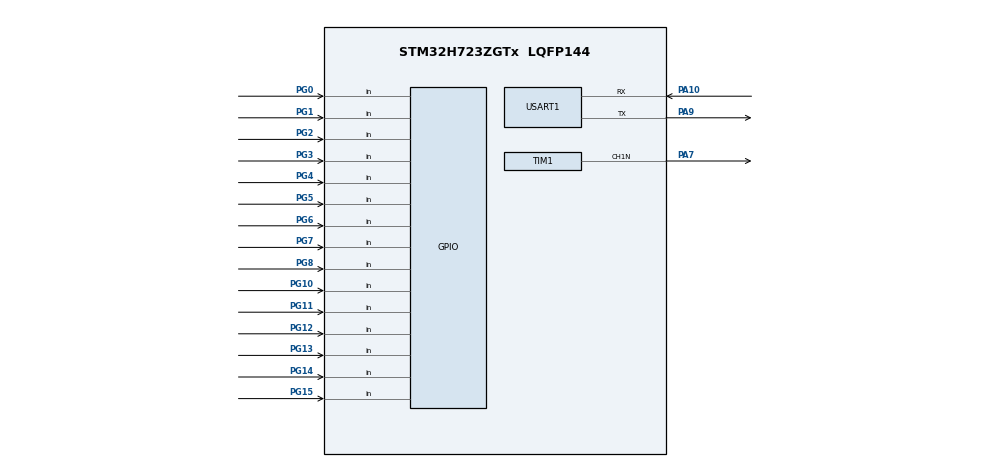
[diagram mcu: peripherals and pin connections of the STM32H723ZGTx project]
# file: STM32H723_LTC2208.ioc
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CORTEX_M7.AccessPermission_Spec=MPU_REGION_FULL_ACCESS
CORTEX_M7.BaseAddress_Spec=0x24000000
CORTEX_M7.CPU_DCache=Enabled
CORTEX_M7.CPU_ICache=Enabled
CORTEX_M7.DisableExec_Spec=MPU_INSTRUCTION_ACCESS_ENABLE
CORTEX_M7.IsBufferable_Spec=MPU_ACCESS_BUFFERABLE
CORTEX_M7.IsCacheable_Spec=MPU_ACCESS_CACHEABLE
CORTEX_M7.IsShareable_Spec=MPU_ACCESS_NOT_SHAREABLE
CORTEX_M7.Size_Spec=MPU_REGION_SIZE_512KB
CORTEX_M7.SubRegionDisable_Spec=0x00
CORTEX_M7.TypeExtField_Spec=MPU_TEX_LEVEL1
CORTEX_M7.default_mode_Activation=1
Dma.Request0=TIM1_UP
Dma.TIM1_UP.0.Direction=DMA_PERIPH_TO_MEMORY
Dma.TIM1_UP.0.EventEnable=DISABLE
Dma.TIM1_UP.0.FIFOMode=DMA_FIFOMODE_DISABLE
Dma.TIM1_UP.0.Instance=DMA1_Stream0
Dma.TIM1_UP.0.MemDataAlignment=DMA_MDATAALIGN_HALFWORD
Dma.TIM1_UP.0.MemInc=DMA_MINC_ENABLE
Dma.TIM1_UP.0.Mode=DMA_CIRCULAR
Dma.TIM1_UP.0.PeriphDataAlignment=DMA_PDATAALIGN_HALFWORD
Dma.TIM1_UP.0.PeriphInc=DMA_PINC_DISABLE
Dma.TIM1_UP.0.Polarity=HAL_DMAMUX_REQ_GEN_RISING
Dma.TIM1_UP.0.Priority=DMA_PRIORITY_VERY_HIGH
Dma.TIM1_UP.0.RequestNumber=1
Dma.TIM1_UP.0.SignalID=NONE
Dma.TIM1_UP.0.SyncEnable=DISABLE
Dma.TIM1_UP.0.SyncPolarity=HAL_DMAMUX_SYNC_NO_EVENT
Dma.TIM1_UP.0.SyncRequestNumber=1
Dma.TIM1_UP.0.SyncSignalID=NONE
Mcu.Family=STM32H7
Mcu.Name=STM32H723ZGTx
Mcu.Package=LQFP144
NVIC.DMA1_Stream0_IRQn=true\:0\:0\:false\:false\:true\:false\:true\:true
NVIC.PriorityGroup=NVIC_PRIORITYGROUP_4
PA10.Mode=Asynchronous
PA10.Signal=USART1_RX
PA13(JTMS/SWDIO).Mode=Serial_Wire
PA13(JTMS/SWDIO).Signal=DEBUG_JTMS-SWDIO
PA14(JTCK/SWCLK).Mode=Serial_Wire
PA14(JTCK/SWCLK).Signal=DEBUG_JTCK-SWCLK
PA7.GPIO_Speed=GPIO_SPEED_FREQ_VERY_HIGH
PA7.Mode=PWM Generation1 CH1N
PA7.Signal=TIM1_CH1N
PA9.Mode=Asynchronous
PA9.Signal=USART1_TX
PG0.Signal=GPIO_Input
PG1.Signal=GPIO_Input
PG10.Signal=GPIO_Input
PG11.Signal=GPIO_Input
PG12.Signal=GPIO_Input
PG13.Signal=GPIO_Input
PG14.Signal=GPIO_Input
PG15.Signal=GPIO_Input
PG2.Signal=GPIO_Input
PG3.Signal=GPIO_Input
PG4.Signal=GPIO_Input
PG5.Signal=GPIO_Input
PG6.Signal=GPIO_Input
PG7.Signal=GPIO_Input
PG8.Signal=GPIO_Input
PH0-OSC_IN.Mode=HSE-External-Oscillator
PH0-OSC_IN.Signal=RCC_OSC_IN
PH1-OSC_OUT.Mode=HSE-External-Oscillator
PH1-OSC_OUT.Signal=RCC_OSC_OUT
ProjectManager.HeapSize=0x200
ProjectManager.StackSize=0x400
ProjectManager.TargetToolchain=MDK-ARM V5.32
RCC.ADCFreq_Value=50390625
RCC.APB1Freq_Value=130000000
RCC.APB2Freq_Value=130000000
RCC.APB3Freq_Value=130000000
RCC.APB4Freq_Value=130000000
RCC.CortexFreq_Value=520000000
RCC.D1PPRE=RCC_APB3_DIV2
RCC.D2PPRE1=RCC_APB1_DIV2
RCC.D2PPRE2=RCC_APB2_DIV2
RCC.D3PPRE=RCC_APB4_DIV2
RCC.DIVM1=5
RCC.DIVN1=104
RCC.DIVP1=1
RCC.HCLKFreq_Value=260000000
RCC.HPRE=RCC_HCLK_DIV2
RCC.PLLFRACN=0
RCC.PLLSourceVirtual=RCC_PLLSOURCE_HSE
RCC.SYSCLKFreq_VALUE=520000000
RCC.SYSCLKSource=RCC_SYSCLKSOURCE_PLLCLK
RCC.USBFreq_Value=260000000
TIM1.AutoReloadPreload=TIM_AUTORELOAD_PRELOAD_ENABLE
TIM1.Channel-PWM\ Generation1\ CH1N=TIM_CHANNEL_1
TIM1.OCFastMode_PWM-PWM\ Generation1\ CH1N=TIM_OCFAST_ENABLE
TIM1.Period=0
TIM1.TIM_MasterOutputTrigger=TIM_TRGO_UPDATE
USART1.VirtualMode-Asynchronous=VM_ASYNC
VP_TIM1_VS_ClockSourceINT.Mode=Internal
board=custom

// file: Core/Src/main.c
/* USER CODE BEGIN Header */
/**
  ******************************************************************************
  * @file           : main.c
  * @brief          : Main program body
  ******************************************************************************
  * @attention
  *
  * Copyright (c) 2025 STMicroelectronics.
  * All rights reserved.
  *
  * This software is licensed under terms that can be found in the LICENSE file
  * in the root directory of this software component.
  * If no LICENSE file comes with this software, it is provided AS-IS.
  *
  ******************************************************************************
  */
/* USER CODE END Header */
#include "main.h"
#include "dma.h"
#include "tim.h"
#include "usart.h"
#include "gpio.h"

void SystemClock_Config(void);
static void MPU_Config(void);

int main(void)
{

  /* MPU Configuration--------------------------------------------------------*/
  MPU_Config();

  /* Enable I-Cache---------------------------------------------------------*/
  SCB_EnableICache();

  /* Enable D-Cache---------------------------------------------------------*/
  SCB_EnableDCache();

  /* MCU Configuration--------------------------------------------------------*/

  /* Reset of all peripherals, Initializes the Flash interface and the Systick. */
  HAL_Init();

  /* Configure the system clock */
  SystemClock_Config();

  /* Initialize all configured peripherals */
  MX_GPIO_Init();
  MX_DMA_Init();
  MX_TIM1_Init();
  MX_USART1_UART_Init();
  /* USER CODE BEGIN 2 */

	TIM1->ARR = 2500-1;
	TIM1->CCR1 = 1250;
	HAL_TIM_PWM_Start(&htim1, TIM_CHANNEL_1);
	HAL_TIMEx_PWMN_Start(&htim1, TIM_CHANNEL_1);

  /* USER CODE END 2 */

  /* Infinite loop */
  while (1)
  {

  }
}

void SystemClock_Config(void)
{
  RCC_OscInitTypeDef RCC_OscInitStruct = {0};
  RCC_ClkInitTypeDef RCC_ClkInitStruct = {0};

  /** Supply configuration update enable
  */
  HAL_PWREx_ConfigSupply(PWR_LDO_SUPPLY);

  /** Configure the main internal regulator output voltage
  */
  __HAL_PWR_VOLTAGESCALING_CONFIG(PWR_REGULATOR_VOLTAGE_SCALE0);

  while(!__HAL_PWR_GET_FLAG(PWR_FLAG_VOSRDY)) {}

  /** Initializes the RCC Oscillators according to the specified parameters
  * in the RCC_OscInitTypeDef structure.
  */
  RCC_OscInitStruct.OscillatorType = RCC_OSCILLATORTYPE_HSE;
  RCC_OscInitStruct.HSEState = RCC_HSE_ON;
  RCC_OscInitStruct.PLL.PLLState = RCC_PLL_ON;
  RCC_OscInitStruct.PLL.PLLSource = RCC_PLLSOURCE_HSE;
  RCC_OscInitStruct.PLL.PLLM = 5;
  RCC_OscInitStruct.PLL.PLLN = 104;
  RCC_OscInitStruct.PLL.PLLP = 1;
  RCC_OscInitStruct.PLL.PLLQ = 2;
  RCC_OscInitStruct.PLL.PLLR = 2;
  RCC_OscInitStruct.PLL.PLLRGE = RCC_PLL1VCIRANGE_2;
  RCC_OscInitStruct.PLL.PLLVCOSEL = RCC_PLL1VCOWIDE;
  RCC_OscInitStruct.PLL.PLLFRACN = 0;
  if (HAL_RCC_OscConfig(&RCC_OscInitStruct) != HAL_OK)
  {
    Error_Handler();
  }

  /** Initializes the CPU, AHB and APB buses clocks
  */
  RCC_ClkInitStruct.ClockType = RCC_CLOCKTYPE_HCLK|RCC_CLOCKTYPE_SYSCLK
                              |RCC_CLOCKTYPE_PCLK1|RCC_CLOCKTYPE_PCLK2
                              |RCC_CLOCKTYPE_D3PCLK1|RCC_CLOCKTYPE_D1PCLK1;
  RCC_ClkInitStruct.SYSCLKSource = RCC_SYSCLKSOURCE_PLLCLK;
  RCC_ClkInitStruct.SYSCLKDivider = RCC_SYSCLK_DIV1;
  RCC_ClkInitStruct.AHBCLKDivider = RCC_HCLK_DIV2;
  RCC_ClkInitStruct.APB3CLKDivider = RCC_APB3_DIV2;
  RCC_ClkInitStruct.APB1CLKDivider = RCC_APB1_DIV2;
  RCC_ClkInitStruct.APB2CLKDivider = RCC_APB2_DIV2;
  RCC_ClkInitStruct.APB4CLKDivider = RCC_APB4_DIV2;

  if (HAL_RCC_ClockConfig(&RCC_ClkInitStruct, FLASH_LATENCY_3) != HAL_OK)
  {
    Error_Handler();
  }
}

/* MPU Configuration */

void MPU_Config(void)
{
  MPU_Region_InitTypeDef MPU_InitStruct = {0};

  /* Disables the MPU */
  HAL_MPU_Disable();

  /** Initializes and configures the Region and the memory to be protected
  */
  MPU_InitStruct.Enable = MPU_REGION_ENABLE;
  MPU_InitStruct.Number = MPU_REGION_NUMBER0;
  MPU_InitStruct.BaseAddress = 0x24000000;
  MPU_InitStruct.Size = MPU_REGION_SIZE_512KB;
  MPU_InitStruct.SubRegionDisable = 0x00;
  MPU_InitStruct.TypeExtField = MPU_TEX_LEVEL1;
  MPU_InitStruct.AccessPermission = MPU_REGION_FULL_ACCESS;
  MPU_InitStruct.DisableExec = MPU_INSTRUCTION_ACCESS_ENABLE;
  MPU_InitStruct.IsShareable = MPU_ACCESS_NOT_SHAREABLE;
  MPU_InitStruct.IsCacheable = MPU_ACCESS_CACHEABLE;
  MPU_InitStruct.IsBufferable = MPU_ACCESS_BUFFERABLE;

  HAL_MPU_ConfigRegion(&MPU_InitStruct);
  /* Enables the MPU */
  HAL_MPU_Enable(MPU_PRIVILEGED_DEFAULT);

}

void Error_Handler(void)
{
  __disable_irq();
  while (1)
  {
  }
}
